# NANO100BN_v1 register map
File version: 1.0
Registers are 32-bit, read-write, reset 0x0 unless marked. A register's access mark holds for its fields unless they carry their own. Offsets are from the block's base; [hi:lo] are bit positions.

## VDMA — VDMA Register Map
Base 0x50008000
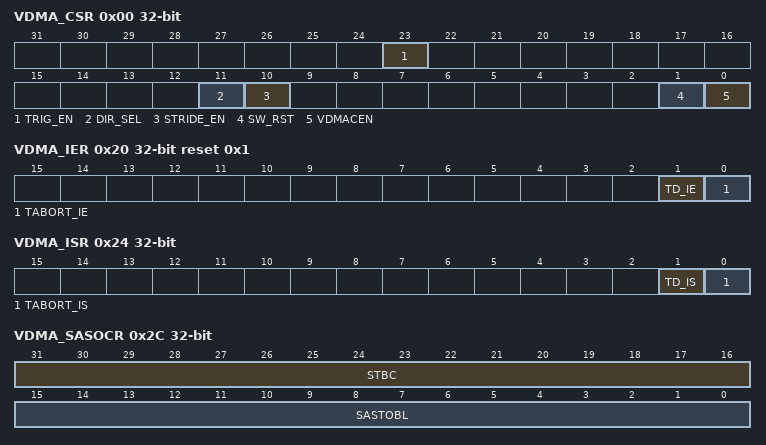
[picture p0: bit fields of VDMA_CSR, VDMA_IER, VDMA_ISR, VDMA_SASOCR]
0x00 VDMA_CSR — VDMA Control Register
  [23] TRIG_EN — TRIG_EN. Note1: When VDMA transfer is completed, this bit will be cleared automatically. Note2: If the bus error occurs, all VDMA transfer will be stopped. Software must reset all VDMA channel, and then trig again.
    0=No effect; 1=VDMA data read or write transfer Enabled
  [11] DIR_SEL — Transfer Source/Destination Address Direction Select
    0=Transfer address is incremented successively; 1=Transfer address is decremented successively
  [10] STRIDE_EN — Stride Mode Enable
    0=Stride transfer mode Disabled; 1=Stride transfer mode Enabled
  [1] SW_RST — Software Engine Reset
    0=No effect; 1=Reset the internal state machine and pointers. The contents of control register will not be cleared. This bit will be auto cleared after few clock cycles
  [0] VDMACEN — VDMA Channel Enable. Setting this bit to "1" enables VDMA's operation. If this bit is cleared, VDMA will ignore all VDMA request and force Bus Master into IDLE state. Note: SW_RST will clear this bit.
0x04 VDMA_SAR — VDMA Source Address Register
  [31:0] VDMA_SAR — VDMA Transfer Source Address Register. This field indicates a 32-bit source address of VDMA.
0x08 VDMA_DAR — VDMA Destination Address Register
  [31:0] VDMA_DAR — VDMA Transfer Destination Address Register. This field indicates a 32-bit destination address of VDMA.
0x0C VDMA_BCR — VDMA Transfer Byte Count Register
  [15:0] VDMA_BCR — VDMA Transfer Byte Count Register. This field indicates a 16-bit transfer byte count of VDMA.
0x14 VDMA_CSAR ro — VDMA Current Source Address Register
  [31:0] VDMA_CSAR — VDMA Current Source Address Register (Read Only). This field indicates the source address where the VDMA transfer is just occurring.
0x18 VDMA_CDAR ro — VDMA Current Destination Address Register
  [31:0] VDMA_CDAR — VDMA Current Destination Address Register (Read Only). This field indicates the destination address where the VDMA transfer is just occurring.
0x1C VDMA_CBCR ro — VDMA Current Transfer Byte Count Register
  [15:0] VDMA_CBCR — VDMA Current Byte Count Register (Read Only). This field indicates the current remained byte count of VDMA.
0x20 VDMA_IER reset 0x1 — VDMA Interrupt Enable Register
  [1] TD_IE — VDMA Transfer Done Interrupt Enable
    0=Disabled interrupt generator during VDMA transfer done; 1=Enabled interrupt generator during VDMA transfer done
  [0] TABORT_IE — VDMA Read/Write Target Abort Interrupt Enable
    0=Disabled target abort interrupt generation during VDMA transfer; 1=Enabled target abort interrupt generation during VDMA transfer
0x24 VDMA_ISR — VDMA Interrupt Status Register
  [1] TD_IS — Transfer Done Interrupt Status Flag. This bit indicates that VDMA has finished all transfer. Note: This bit is cleared by writing "1" to itself.
    0=Not finished yet; 1=Done
  [0] TABORT_IS — VDMA Read/Write Target Abort Interrupt Status Flag. Note1: This bit is cleared by writing "1" to itself. Note2: The VDMA_ISR [TABORT_IF] indicate bus master received ERROR response or not, if bus master received occur it means that target abort is happened. VDMA controller will stop transfer and respond this event to software then go to IDLE state. When target abort occurred, software must reset VDMA controller, and then transfer those data again.
    0=No bus ERROR response received; 1=Bus ERROR response received
0x2C VDMA_SASOCR — VDMA Source Address Stride Offset Register
  [31:16] STBC — VDMA Stride Transfer Byte Count. The 16-bit register defines the stride transfer byte count of each row.
  [15:0] SASTOBL — VDMA Source Address Stride Offset Byte Length. The 16-bit register defines the source address stride transfer offset count of each row.
0x30 VDMA_DASOCR — VDMA Destination Address Stride Offset Register
  [15:0] DASTOBL — VDMA Destination Address Stride Offset Byte Length. The 16-bit register defines the destination address stride transfer offset count of each row.
0x80 VDMA_BUF0 ro — VDMA Internal Buffer FIFO 0
  [31:0] VDMA_BUF0 — VDMA Internal Buffer FIFO 0 (Read Only). VDMA channel has its own 2 words internal buffer.
0x84 VDMA_BUF1 ro — VDMA Internal Buffer FIFO 1
  [31:0] VDMA_BUF1 — VDMA Internal Buffer FIFO 1 (Read Only). VDMA channel has its own 2 words internal buffer.
